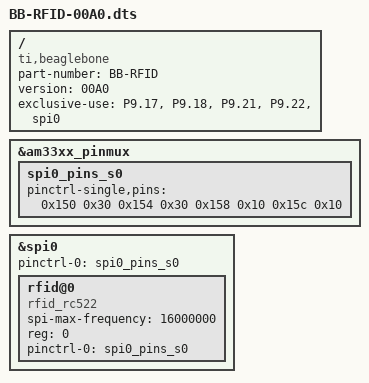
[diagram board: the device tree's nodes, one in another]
/*  
* Copyright (C) 2012 Texas Instruments Incorporated - http://www.ti.com/
*
* This program is free software; you can redistribute it and/or modify
* it under the terms of the GNU General Purpose License Version 2 as
* published by the Free Software Foundation
*
* by Saak Dertadian (s.dertadian@gmail.com)
*
*/

/dts-v1/;
/plugin/;

/ {
	compatible = "ti,beaglebone", "ti,beaglebone-black";

	/* identification */
	part-number = "BB-RFID";
	version = "00A0";

	/* state the resources this cape uses */
	exclusive-use =
		/* the pin header uses */
		"P9.17",	/* spi0_cs0 */
		"P9.18",	/* spi0_d1 */
		"P9.21",	/* spi0_d0 */
		"P9.22",	/* spi0_sclk */
		/* the hardware ip uses */
		"spi0";

	fragment@0
	{
		target = <&am33xx_pinmux>;
		__overlay__
		{
			spi0_pins_s0: spi0_pins_s0
			{
				pinctrl-single,pins = <
					0x150 0x30  /* spi0_sclk, INPUT_PULLUP  | MODE0 */
					0x154 0x30  /* spi0_d0,   INPUT_PULLUP  | MODE0 */
					0x158 0x10  /* spi0_d1,   OUTPUT_PULLUP | MODE0 */
					0x15c 0x10  /* spi0_cs0,  OUTPUT_PULLUP | MODE0 */
				>;
			};
		};
	};

	fragment@1
	{
		target = <&spi0>;
		__overlay__
		{
			#address-cells = <1>;
			#size-cells = <0>;

			status = "okay";
			pinctrl-names = "default";
			pinctrl-0 = <&spi0_pins_s0>;

			rfid@0
			{
				#address-cells = <1>;
				#size-cells = <0>;

				compatible = "rfid_rc522";
				spi-max-frequency = <16000000>;
				reg = <0>;

				pinctrl-names = "default";
				pinctrl-0 = <&spi0_pins_s0>;
			};
		};
	};
};
